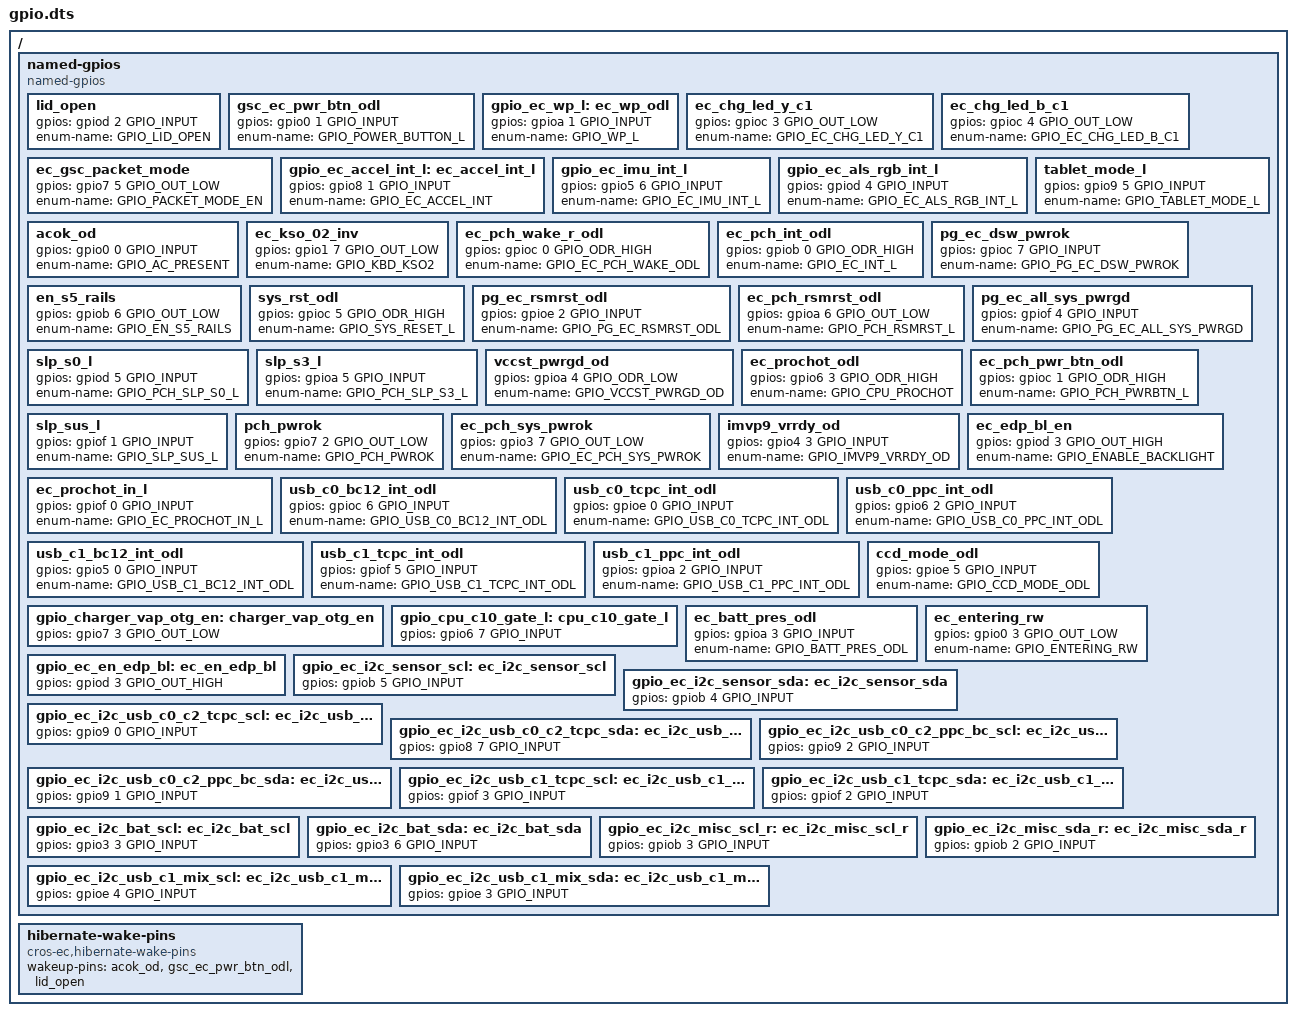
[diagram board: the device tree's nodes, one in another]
/* Copyright 2021 The Chromium OS Authors. All rights reserved.
 * Use of this source code is governed by a BSD-style license that can be
 * found in the LICENSE file.
 */

/ {
	named-gpios {
		compatible = "named-gpios";

		lid_open: lid_open {
			gpios = <&gpiod 2 GPIO_INPUT>;
			enum-name = "GPIO_LID_OPEN";
		};

		gsc_ec_pwr_btn_odl: gsc_ec_pwr_btn_odl {
			gpios = <&gpio0 1 GPIO_INPUT>;
			enum-name = "GPIO_POWER_BUTTON_L";
		};

		gpio_ec_wp_l: ec_wp_odl {
			#gpio-cells = <0>;
			gpios = <&gpioa 1 GPIO_INPUT>;
			enum-name = "GPIO_WP_L";
		};

		ec_chg_led_y_c1 {
			gpios = <&gpioc 3 GPIO_OUT_LOW>;
			enum-name = "GPIO_EC_CHG_LED_Y_C1";
		};

		ec_chg_led_b_c1 {
			gpios = <&gpioc 4 GPIO_OUT_LOW>;
			enum-name = "GPIO_EC_CHG_LED_B_C1";
		};

		ec_gsc_packet_mode {
			gpios = <&gpio7 5 GPIO_OUT_LOW>;
			enum-name = "GPIO_PACKET_MODE_EN";
		};
		gpio_ec_accel_int_l: ec_accel_int_l {
			gpios = <&gpio8 1 GPIO_INPUT>;
			enum-name = "GPIO_EC_ACCEL_INT";
		};
		gpio_ec_imu_int_l: gpio_ec_imu_int_l {
			gpios = <&gpio5 6 GPIO_INPUT>;
			enum-name = "GPIO_EC_IMU_INT_L";
		};
		gpio_ec_als_rgb_int_l: gpio_ec_als_rgb_int_l {
			gpios = <&gpiod 4 GPIO_INPUT>;
			enum-name = "GPIO_EC_ALS_RGB_INT_L";
		};
		tablet_mode_l {
			gpios = <&gpio9 5 GPIO_INPUT>;
			enum-name = "GPIO_TABLET_MODE_L";
		};
		acok_od: acok_od {
			gpios = <&gpio0 0 GPIO_INPUT>;
			enum-name = "GPIO_AC_PRESENT";
		};
		ec_kso_02_inv {
			gpios = <&gpio1 7 GPIO_OUT_LOW>;
			enum-name = "GPIO_KBD_KSO2";
		};
		ec_pch_wake_r_odl {
			gpios = <&gpioc 0 GPIO_ODR_HIGH>;
			enum-name = "GPIO_EC_PCH_WAKE_ODL";
		};
		ec_pch_int_odl {
			gpios = <&gpiob 0 GPIO_ODR_HIGH>;
			enum-name = "GPIO_EC_INT_L";
		};
		pg_ec_dsw_pwrok {
			gpios = <&gpioc 7 GPIO_INPUT>;
			enum-name = "GPIO_PG_EC_DSW_PWROK";
		};
		en_s5_rails {
			gpios = <&gpiob 6 GPIO_OUT_LOW>;
			enum-name = "GPIO_EN_S5_RAILS";
		};
		sys_rst_odl {
			gpios = <&gpioc 5 GPIO_ODR_HIGH>;
			enum-name = "GPIO_SYS_RESET_L";
		};
		pg_ec_rsmrst_odl {
			gpios = <&gpioe 2 GPIO_INPUT>;
			enum-name = "GPIO_PG_EC_RSMRST_ODL";
		};
		ec_pch_rsmrst_odl {
			gpios = <&gpioa 6 GPIO_OUT_LOW>;
			enum-name = "GPIO_PCH_RSMRST_L";
		};
		pg_ec_all_sys_pwrgd {
			gpios = <&gpiof 4 GPIO_INPUT>;
			enum-name = "GPIO_PG_EC_ALL_SYS_PWRGD";
		};
		slp_s0_l {
			gpios = <&gpiod 5 GPIO_INPUT>;
			enum-name = "GPIO_PCH_SLP_S0_L";
		};
		slp_s3_l {
			gpios = <&gpioa 5 GPIO_INPUT>;
			enum-name = "GPIO_PCH_SLP_S3_L";
		};
		vccst_pwrgd_od {
			gpios = <&gpioa 4 GPIO_ODR_LOW>;
			enum-name = "GPIO_VCCST_PWRGD_OD";
		};
		ec_prochot_odl {
			gpios = <&gpio6 3 GPIO_ODR_HIGH>;
			enum-name = "GPIO_CPU_PROCHOT";
		};
		ec_pch_pwr_btn_odl {
			gpios = <&gpioc 1 GPIO_ODR_HIGH>;
			enum-name = "GPIO_PCH_PWRBTN_L";
		};
		slp_sus_l {
			gpios = <&gpiof 1 GPIO_INPUT>;
			enum-name = "GPIO_SLP_SUS_L";
		};
		pch_pwrok {
			gpios = <&gpio7 2 GPIO_OUT_LOW>;
			enum-name = "GPIO_PCH_PWROK";
		};
		ec_pch_sys_pwrok {
			gpios = <&gpio3 7 GPIO_OUT_LOW>;
			enum-name = "GPIO_EC_PCH_SYS_PWROK";
		};
		imvp9_vrrdy_od {
			gpios = <&gpio4 3 GPIO_INPUT>;
			enum-name = "GPIO_IMVP9_VRRDY_OD";
		};
		ec_edp_bl_en {
			gpios = <&gpiod 3 GPIO_OUT_HIGH>;
			enum-name = "GPIO_ENABLE_BACKLIGHT";
		};
		ec_prochot_in_l {
			gpios = <&gpiof 0 GPIO_INPUT>;
			enum-name = "GPIO_EC_PROCHOT_IN_L";
		};
		usb_c0_bc12_int_odl {
			gpios = <&gpioc 6 GPIO_INPUT>;
			enum-name = "GPIO_USB_C0_BC12_INT_ODL";
		};
		usb_c0_tcpc_int_odl {
			gpios = <&gpioe 0 GPIO_INPUT>;
			enum-name = "GPIO_USB_C0_TCPC_INT_ODL";
		};
		usb_c0_ppc_int_odl {
			gpios = <&gpio6 2 GPIO_INPUT>;
			enum-name = "GPIO_USB_C0_PPC_INT_ODL";
		};
		usb_c1_bc12_int_odl {
			gpios = <&gpio5 0 GPIO_INPUT>;
			enum-name = "GPIO_USB_C1_BC12_INT_ODL";
		};
		usb_c1_tcpc_int_odl {
			gpios = <&gpiof 5 GPIO_INPUT>;
			enum-name = "GPIO_USB_C1_TCPC_INT_ODL";
		};
		usb_c1_ppc_int_odl {
			gpios = <&gpioa 2 GPIO_INPUT>;
			enum-name = "GPIO_USB_C1_PPC_INT_ODL";
		};
		ccd_mode_odl {
			gpios = <&gpioe 5 GPIO_INPUT>;
			enum-name = "GPIO_CCD_MODE_ODL";
		};
		gpio_charger_vap_otg_en: charger_vap_otg_en {
			gpios = <&gpio7 3 GPIO_OUT_LOW>;
		};
		gpio_cpu_c10_gate_l: cpu_c10_gate_l {
			gpios = <&gpio6 7 GPIO_INPUT>;
		};
		ec_batt_pres_odl {
			gpios = <&gpioa 3 GPIO_INPUT>;
			enum-name = "GPIO_BATT_PRES_ODL";
		};
		ec_entering_rw {
			gpios = <&gpio0 3 GPIO_OUT_LOW>;
			enum-name = "GPIO_ENTERING_RW";
		};
		gpio_ec_en_edp_bl: ec_en_edp_bl {
			gpios = <&gpiod 3 GPIO_OUT_HIGH>;
		};
		gpio_ec_i2c_sensor_scl: ec_i2c_sensor_scl {
			gpios = <&gpiob 5 GPIO_INPUT>;
		};
		gpio_ec_i2c_sensor_sda: ec_i2c_sensor_sda {
			gpios = <&gpiob 4 GPIO_INPUT>;
		};
		gpio_ec_i2c_usb_c0_c2_tcpc_scl: ec_i2c_usb_c0_c2_tcpc_scl {
			gpios = <&gpio9 0 GPIO_INPUT>;
		};
		gpio_ec_i2c_usb_c0_c2_tcpc_sda: ec_i2c_usb_c0_c2_tcpc_sda {
			gpios = <&gpio8 7 GPIO_INPUT>;
		};
		gpio_ec_i2c_usb_c0_c2_ppc_bc_scl: ec_i2c_usb_c0_c2_ppc_bc_scl {
			gpios = <&gpio9 2 GPIO_INPUT>;
		};
		gpio_ec_i2c_usb_c0_c2_ppc_bc_sda: ec_i2c_usb_c0_c2_ppc_bc_sda {
			gpios = <&gpio9 1 GPIO_INPUT>;
		};
		gpio_ec_i2c_usb_c1_tcpc_scl: ec_i2c_usb_c1_tcpc_scl {
			gpios = <&gpiof 3 GPIO_INPUT>;
		};
		gpio_ec_i2c_usb_c1_tcpc_sda: ec_i2c_usb_c1_tcpc_sda {
			gpios = <&gpiof 2 GPIO_INPUT>;
		};
		gpio_ec_i2c_bat_scl: ec_i2c_bat_scl {
			gpios = <&gpio3 3 GPIO_INPUT>;
		};
		gpio_ec_i2c_bat_sda: ec_i2c_bat_sda {
			gpios = <&gpio3 6 GPIO_INPUT>;
		};
		gpio_ec_i2c_misc_scl_r: ec_i2c_misc_scl_r {
			gpios = <&gpiob 3 GPIO_INPUT>;
		};
		gpio_ec_i2c_misc_sda_r: ec_i2c_misc_sda_r {
			gpios = <&gpiob 2 GPIO_INPUT>;
		};
		gpio_ec_i2c_usb_c1_mix_scl: ec_i2c_usb_c1_mix_scl {
			gpios = <&gpioe 4 GPIO_INPUT>;
		};
		gpio_ec_i2c_usb_c1_mix_sda: ec_i2c_usb_c1_mix_sda {
			gpios = <&gpioe 3 GPIO_INPUT>;
		};
	};

	hibernate-wake-pins {
		compatible = "cros-ec,hibernate-wake-pins";
		wakeup-pins = <
			&acok_od
			&gsc_ec_pwr_btn_odl
			&lid_open
		>;
	};
};
